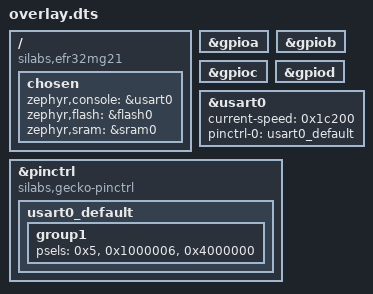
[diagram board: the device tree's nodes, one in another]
/ {
	compatible = "silabs,efr32mg21", "silabs,slwrb4180a";
	chosen {
		zephyr,console = &usart0;
		zephyr,flash = &flash0;
		zephyr,sram = &sram0;
	};
};
&gpioa{
	status = "okay";
};
&gpiob{
	status = "okay";
};
&gpioc{
	status = "okay";
};
&gpiod{
	status = "okay";
};
&usart0{
	status = "okay";
	current-speed = < 0x1c200 >;
	pinctrl-0 = < &usart0_default >;
	pinctrl-names = "default";
};
&pinctrl{
	compatible = "silabs,gecko-pinctrl";
	usart0_default: usart0_default {
		group1 {
			psels = < 0x5 >, < 0x1000006 >, < 0x4000000 >;
		};
	};
};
